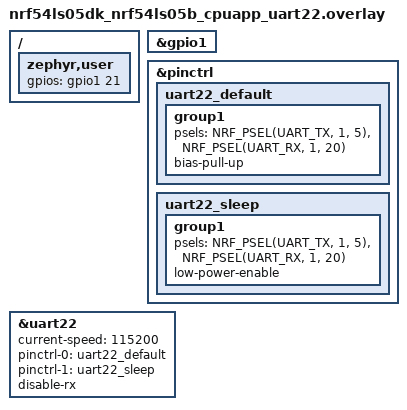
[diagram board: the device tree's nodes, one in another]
/ {
	zephyr,user {
		gpios = <&gpio1 21 GPIO_ACTIVE_HIGH>;
	};
};

&gpio1 {
	status = "okay";
};

&pinctrl {
	uart22_default: uart22_default {
		group1 {
			psels = <NRF_PSEL(UART_TX, 1, 5)>,
				<NRF_PSEL(UART_RX, 1, 20)>;
			bias-pull-up;
		};
	};

	uart22_sleep: uart22_sleep {
		group1 {
			psels = <NRF_PSEL(UART_TX, 1, 5)>,
				<NRF_PSEL(UART_RX, 1, 20)>;
			low-power-enable;
		};
	};
};

dut: &uart22 {
	status = "okay";
	current-speed = <115200>;
	pinctrl-0 = <&uart22_default>;
	pinctrl-1 = <&uart22_sleep>;
	pinctrl-names = "default", "sleep";
	disable-rx;
};
